# a34m41x register map
Vendor: ABOV Semiconductor Co., Ltd.; File version: 1.0
CPU: CM4 r0p1, little endian, MPU, FPU, VTOR, 4 interrupt priority bits
Registers are 32-bit, read-write, reset 0x0 unless marked. A register's access mark holds for its fields unless they carry their own. Offsets are from the block's base; [hi:lo] are bit positions; {n}, {i} and the like mark numbered series; 'fields as' and 'values as' point back to an identical list.

## CAN — Controller Area Network
Base 0x40007000
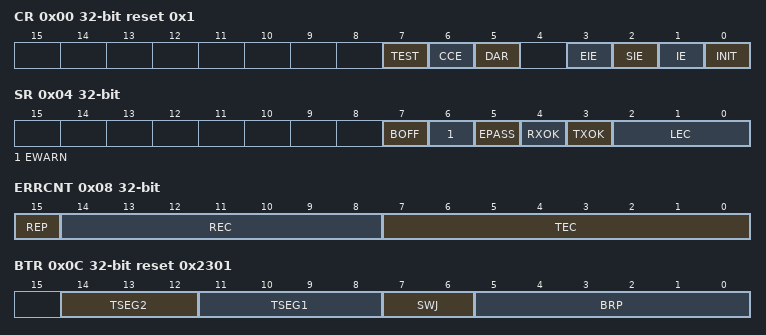
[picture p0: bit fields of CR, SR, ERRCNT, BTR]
0x00 CR reset 0x1 — CAN Control Register
  [7] TEST — Test Mode Enable Bit
    0=Normal Mode; 1=TEST (Test Mode)
  [6] CCE — Configuration Change Enable Bit
  [5] DAR — Automatic Re-transmit Enable Bit
    0=Disable; 1=Enable
  [3] EIE — Error Interrupt Enable Bit
    0=Disable; 1=Enable
  [2] SIE — Status Change Interrupt Enable Bit
    0=Disable; 1=Enable
  [1] IE — CAN Interrupt Enable Bit
    0=Disable; 1=Enable
  [0] INIT — Internal Initialization Pending
    0=Normal Operation; 1=Initialization is started
0x04 SR ro — CAN Status Register
  [7] BOFF — Bus Off Status
  [6] EWARN — Error Warning Status
  [5] EPASS rw — Error Passive
  [4] RXOK — Received a Message Successfully
  [3] TXOK — Transmitted a Message Successfully
  [2:0] LEC — Last Error Code
    0=No_Error; 1=Stuff_Error; 2=Form_Error; 3=Acknowledgment_Error; 4=Bit1_Error; 5=Bit0_Error; 6=CRC_Error
0x08 ERRCNT ro — CAN Error Counter Register
  [15] REP — Receive Error Passive
  [14:8] REC — Receive Error Count
  [7:0] TEC — Transmit Error Count
0x0C BTR reset 0x2301 — CAN Bit Timing Register
  [14:12] TSEG2 — Timing Segment 2
  [11:8] TSEG1 — Timing Segment 1
  [7:6] SWJ — Synchronous Width Jump
  [5:0] BRP — Baud Rate Prescaler
0x10 IER — CAN Interrupt Enable Register
  [15:0] INTID — Interrupt Identifier
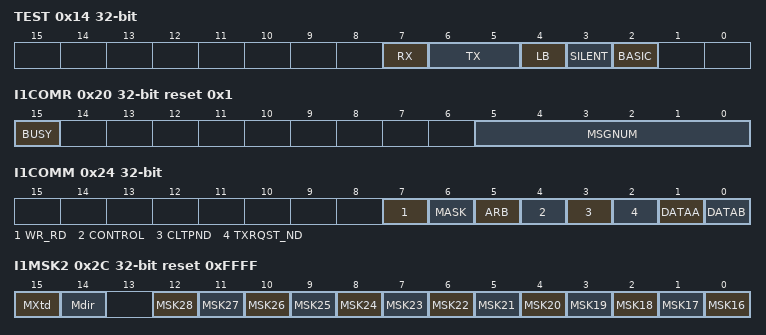
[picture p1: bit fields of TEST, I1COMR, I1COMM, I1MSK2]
0x14 TEST — CAN Test Register
  [7] RX ro — Monitors the actual value of the CAN_RX Pin
  [6:5] TX wo — Control of CAN_TX Pin
    0=Reset Value, CAN_TX is controlled by the CAN Core; 1=Sample Point cna be monitored at CAN_TX Pin; 2=Dominan_Value (CAN_TX pin drivers a dominant("0") value); 3=Recessive_Value (CAN_TX pin drivers a recessive("1") value)
  [4] LB wo — Loop Back Mode (Receiving its own transmission)
    0=Disable; 1=Enable
  [3] SILENT wo — Silent Mode (Never Send Dominant Bits)
    0=Normal Mode; 1=Silent Mode
  [2] BASIC wo — Basic Mode (Message RAM is not abailable)
    0=regular mode (message RAM is used as transmit and receive buffer); 1=IF1_TX_IF2_RX (IF1 register are used as transmit buffers and IF2 register used as receive buffer)
0x18 BRPEXT wo — CAN BRP Extend Register
  [3:0] BRPE — Baud Rate
0x1C EN — CAN Enable Register
  [0] EN — CAN Module Enable Bit
0x20 I1COMR reset 0x1 — CAN Interface 1 Command Request Register
  [15] BUSY — Busy Flag (Write Access Only When Busy = '0')
  [5:0] MSGNUM — Message Number
0x24 I1COMM — CAN Interface1 Command Mask Register
  [7] WR_RD — Write/Read
    0=Read Data From the Message Object addressed by the command request register into the selected interface register; 1=Write data from the selected interface register th the Message object addressed by the command request register
  [6] MASK — Access interface X Mask Bits
    0=Unchanged (Mask Bits unchanged); 1=changed (read/write identifier mask + Mdir + MXtd)
  [5] ARB — Access Interface X Arbitration
    0=unchanged (Arbitration bits unchanged); 1=changed (read/write identifier mask + Mdir + MXtd)
  [4] CONTROL — Access Interface X Message Control Bits
    0=unchanged (control Bits unchanged); 1=changed (read/write conrol bits)
  [3] CLTPND — Clear(Reset) Interface X Clear Interrupt Pending
    0=Pending (Interrupt Pending Bit remains unchanged when reading the message object); 1=Clear Interrupt pending bit when reading the message object
  [2] TXRQST_ND — Write(TXRQST) - Access transmission request / read(ND) - New Data Bit
    0=Unchanged (Write - Tx Request bit unchanged / Read - New Data(NewDat) bit unchanged); 1=Changed (Write - Set Tx Request Bit / Read - Reset NewDat Bit)
  [1] DATAA — Access Data Byte 0-3
    0=Unchanged (Data Byte 0-3 Unchanged); 1=Changed (Read/Write Data Byte 0-3)
  [0] DATAB — Access Data Byte 4-7
    0=Unchanged (Data Byte 4-7 Unchanged); 1=Changed (Read/Write Data Byte 4-7)
0x28 I1MSK1 reset 0xFFFF — CAN Interface1 Mask1 Register
  [15:0] MSK1 — Identifier Mask Standard Message
0x2C I1MSK2 reset 0xFFFF — CAN Interface1 Mask2 Register
  [15] MXtd — Mask Extended Identifier
  [14] Mdir — Mask Message Direction
  [n-16] MSK{n} (n=18..28) — Identifier Mask Standard Message
  [1] MSK17 — Identifier Mask Extended Message
  [0] MSK16 — Identifier Mask Extended Message
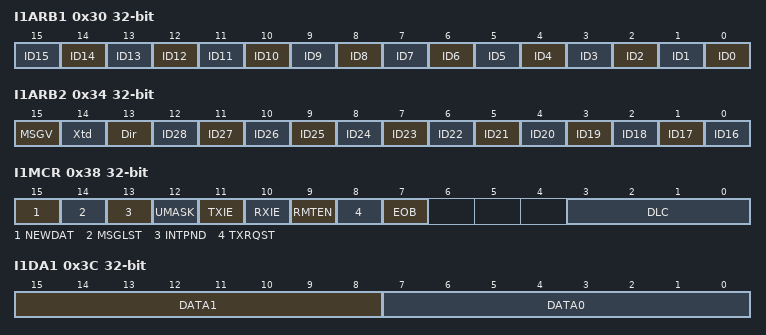
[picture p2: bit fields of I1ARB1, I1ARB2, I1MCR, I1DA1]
0x30 I1ARB1 — CAN Interface1 Arbitration1 Register
  [n] ID{n} (n=0..15) — Identifier Extended Message
0x34 I1ARB2 — CAN Interface1 Arbitration2 Register
  [15] MSGV — Message Validation
  [14] Xtd — Extended Identifier
  [13] Dir — Message Direction
  [n-16] ID{n} (n=18..28) — Identifier Standard Message
  [1] ID17 — Identifier Extended Message
  [0] ID16 — Identifier Extended Message
0x38 I1MCR — CAN Interface1 Message Control Register
  [15] NEWDAT — New Data
  [14] MSGLST — Message Lost(Only valid for direction = receive)
  [13] INTPND — Interrupt Pending
  [12] UMASK — Use Identifier Mask
  [11] TXIE — Transmit Interrupt Enable
  [10] RXIE — Receive Interrupt Enable
  [9] RMTEN — Remote Enable
  [8] TXRQST — Transmit Request
  [7] EOB — End of Buffer (For normal Operation, This bit must be set to one)
  [3:0] DLC — Data Length Code, Number of Data Bytes
0x3C I1DA1 — CAN Interface1 Data A1 Register
  [15:8] DATA1 — DATA1 : Shifter Register Byte 1
  [7:0] DATA0 — DATA0 : Shifter Register Byte 0
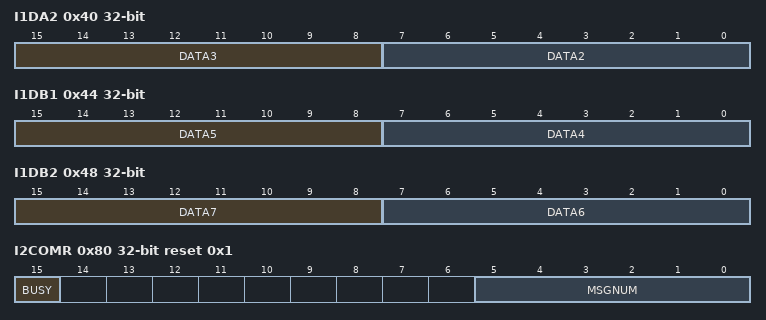
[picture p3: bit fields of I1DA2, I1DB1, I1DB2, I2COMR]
0x40 I1DA2 — CAN Interface1 Data A2 Register
  [15:8] DATA3 — DATA3 : Shifter Register Byte 3
  [7:0] DATA2 — DATA2 : Shifter Register Byte 2
0x44 I1DB1 — CAN Interface1 Data B1 Register
  [15:8] DATA5 — DATA5 : Shifter Register Byte 5
  [7:0] DATA4 — DATA4 : Shifter Register Byte 4
0x48 I1DB2 — CAN Interface1 Data B2 Register
  [15:8] DATA7 — DATA7 : Shifter Register Byte 7
  [7:0] DATA6 — DATA6 : Shifter Register Byte 6
0x80 I2COMR reset 0x1 — CAN Interface 2 Command Request Register
  fields as I1COMR
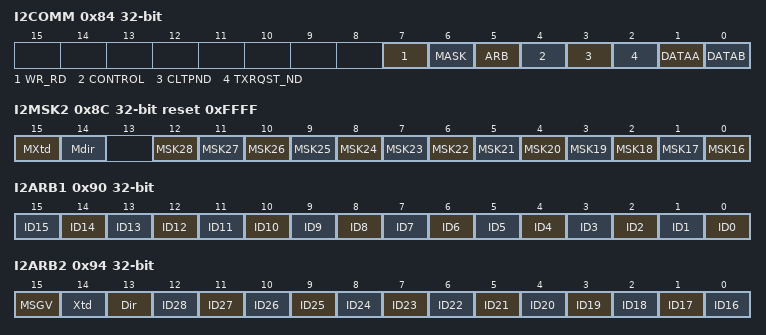
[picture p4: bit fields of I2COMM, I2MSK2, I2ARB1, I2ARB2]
0x84 I2COMM — CAN Interface2 Command Mask Register
  fields as I1COMM
0x88 I2MSK1 reset 0xFFFF — CAN Interface2 Mask1 Register
  [15:0] MSK1 — Identifier Mask Standard Message
0x8C I2MSK2 reset 0xFFFF — CAN Interface2 Mask2 Register
  fields as I1MSK2
0x90 I2ARB1 — CAN Interface2 Arbitration1 Register
  [n] ID{n} (n=0..15) — Identifier Extended Message
0x94 I2ARB2 — CAN Interface2 Arbitration2 Register
  fields as I1ARB2
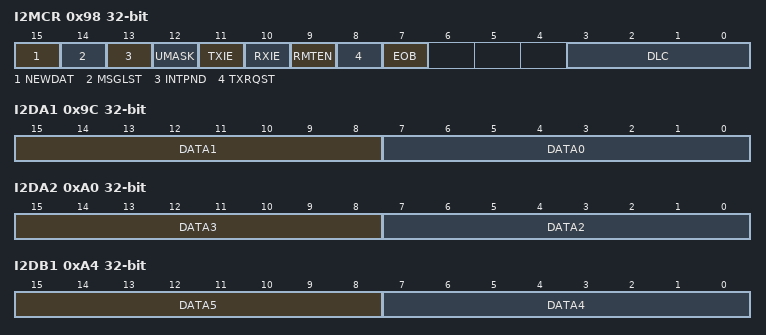
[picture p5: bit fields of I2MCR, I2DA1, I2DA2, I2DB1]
0x98 I2MCR — CAN Interface2 Message Control Register
  fields as I1MCR
0x9C I2DA1 — CAN Interface2 Data A1 Register
  fields as I1DA1
0xA0 I2DA2 — CAN Interface2 Data A2 Register
  fields as I1DA2
0xA4 I2DB1 — CAN Interface2 Data B1 Register
  fields as I1DB1
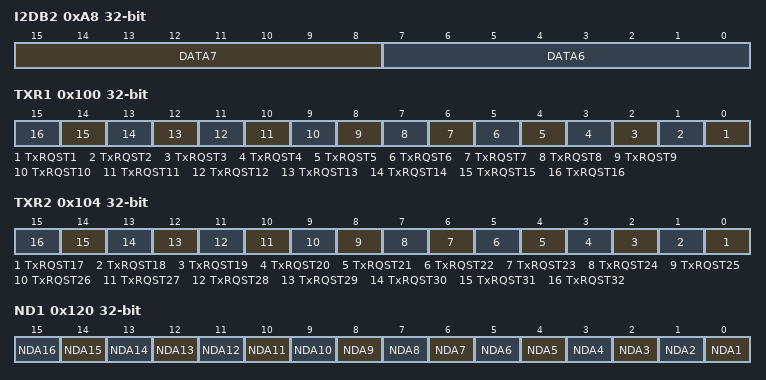
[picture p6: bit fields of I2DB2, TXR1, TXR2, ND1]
0xA8 I2DB2 — CAN Interface2 Data B2 Register
  fields as I1DB2
0x100 TXR1 ro — CAN transmission Request Bit (n=16~1)
  [n-1] TxRQST{n} (n=1..16) — Transmission Request Bit {n}
0x104 TXR2 ro — CAN transmission Request Bit (n=32~17)
  [n-17] TxRQST{n} (n=17..32) — Transmission Request Bit {n}
0x120 ND1 ro — CAN New Data Register (n=16~1)
  [n-1] NDA{n} (n=1..16) — New Data Bit {n}
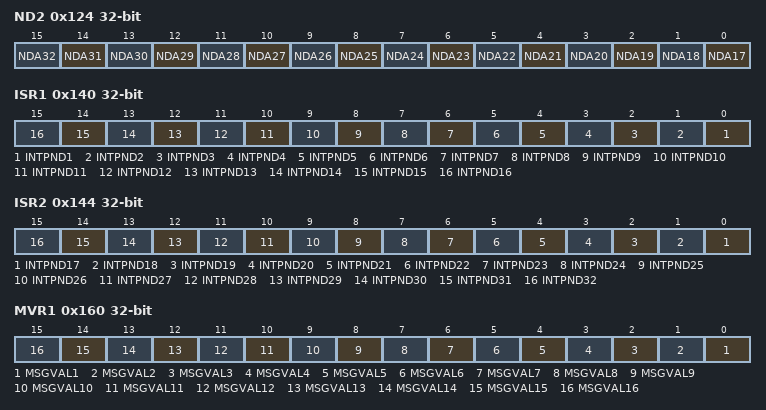
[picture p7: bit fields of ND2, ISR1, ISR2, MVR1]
0x124 ND2 ro — CAN New Data Register (n=32~17)
  [n-17] NDA{n} (n=17..32) — New Data Bit {n}
0x140 ISR1 ro — CAN Interrupt Status Register (n=16~1)
  [n-1] INTPND{n} (n=1..16) — Interrupt Pending Bit {n}
0x144 ISR2 ro — CAN Interrupt Status Register (n=32~17)
  [n-17] INTPND{n} (n=17..32) — Interrupt Pending Bit {n}
0x160 MVR1 ro — CAN Message Validation Register (n=16~1)
  [n-1] MSGVAL{n} (n=1..16) — Message Validation Bit {n}
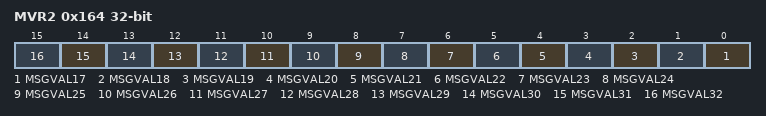
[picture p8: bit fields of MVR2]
0x164 MVR2 ro — CAN Message Validation Register (n=32~17)
  [n-17] MSGVAL{n} (n=17..32) — Message Validation Bit {n}
